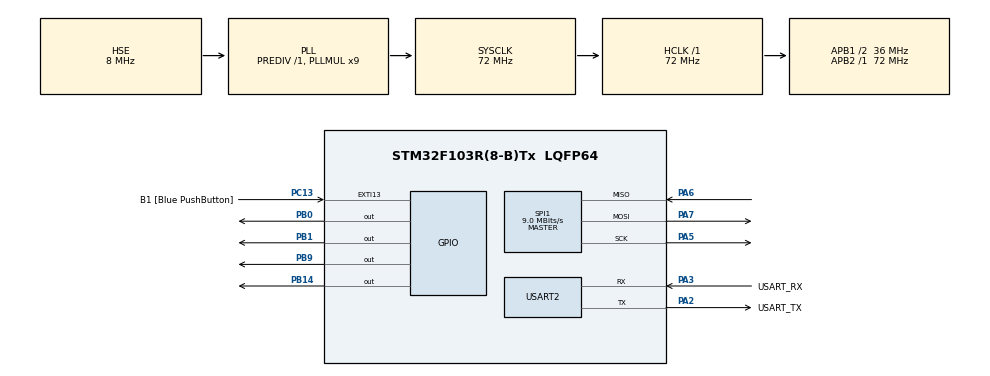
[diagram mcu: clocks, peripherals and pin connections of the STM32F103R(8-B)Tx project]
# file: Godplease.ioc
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Mcu.Family=STM32F1
Mcu.Name=STM32F103R(8-B)Tx
Mcu.Package=LQFP64
NVIC.EXTI15_10_IRQn=true\:0\:0\:false\:false\:true\:true\:true\:true
NVIC.PriorityGroup=NVIC_PRIORITYGROUP_4
PA13.GPIO_Label=TMS
PA13.Mode=Serial_Wire
PA13.Signal=SYS_JTMS-SWDIO
PA14.GPIO_Label=TCK
PA14.Mode=Serial_Wire
PA14.Signal=SYS_JTCK-SWCLK
PA2.GPIO_Label=USART_TX
PA2.GPIO_Mode=GPIO_MODE_AF_PP
PA2.GPIO_PuPd=GPIO_NOPULL
PA2.GPIO_Speed=GPIO_SPEED_FREQ_LOW
PA2.Mode=Asynchronous
PA2.Signal=USART2_TX
PA3.GPIO_Label=USART_RX
PA3.GPIO_Mode=GPIO_MODE_AF_PP
PA3.GPIO_PuPd=GPIO_NOPULL
PA3.GPIO_Speed=GPIO_SPEED_FREQ_LOW
PA3.Mode=Asynchronous
PA3.Signal=USART2_RX
PA5.Mode=Full_Duplex_Master
PA5.Signal=SPI1_SCK
PA6.Mode=Full_Duplex_Master
PA6.Signal=SPI1_MISO
PA7.Mode=Full_Duplex_Master
PA7.Signal=SPI1_MOSI
PB0.Signal=GPIO_Output
PB1.Signal=GPIO_Output
PB14.Signal=GPIO_Output
PB9.Signal=GPIO_Output
PC13-TAMPER-RTC.GPIO_Label=B1 [Blue PushButton]
PC13-TAMPER-RTC.GPIO_PuPd=GPIO_NOPULL
PC13-TAMPER-RTC.Signal=GPXTI13
PC14-OSC32_IN.Signal=RCC_OSC32_IN
PC15-OSC32_OUT.Signal=RCC_OSC32_OUT
PD0-OSC_IN.Mode=HSE-External-Oscillator
PD0-OSC_IN.Signal=RCC_OSC_IN
PD1-OSC_OUT.Mode=HSE-External-Oscillator
PD1-OSC_OUT.Signal=RCC_OSC_OUT
ProjectManager.HeapSize=0x200
ProjectManager.StackSize=0x400
ProjectManager.TargetToolchain=STM32CubeIDE
RCC.AHBFreq_Value=72000000
RCC.APB1CLKDivider=RCC_HCLK_DIV2
RCC.APB1Freq_Value=36000000
RCC.APB1TimFreq_Value=72000000
RCC.APB2Freq_Value=72000000
RCC.APB2TimFreq_Value=72000000
RCC.HCLKFreq_Value=72000000
RCC.PLLMUL=RCC_PLL_MUL9
RCC.PLLSourceVirtual=RCC_PLLSOURCE_HSE
RCC.RTCClockSelection=RCC_RTCCLKSOURCE_LSE
RCC.SYSCLKFreq_VALUE=72000000
RCC.SYSCLKSource=RCC_SYSCLKSOURCE_PLLCLK
RCC.USBFreq_Value=72000000
SPI1.BaudRatePrescaler=SPI_BAUDRATEPRESCALER_8
SPI1.CalculateBaudRate=9.0 MBits/s
SPI1.Direction=SPI_DIRECTION_2LINES
SPI1.Mode=SPI_MODE_MASTER
SPI1.VirtualType=VM_MASTER
TIM2.Prescaler=71
USART2.VirtualMode=VM_ASYNC
VP_TIM2_VS_ClockSourceINT.Mode=Internal
board=NUCLEO-F103RB

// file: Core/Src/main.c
/* USER CODE BEGIN Header */
/**
******************************************************************************
* @file : main.c
* @brief : Main program body
******************************************************************************
* @attention
*
* Copyright (c) 2025 STMicroelectronics.
* All rights reserved.
*
* This software is licensed under terms that can be found in the LICENSE file
* in the root directory of this software component.
* If no LICENSE file comes with this software, it is provided AS-IS.
*
******************************************************************************
*/
/* USER CODE END Header */
#include "main.h"
#include "stdio.h"
#include "RC522.h"
#include "string.h"

SPI_HandleTypeDef hspi1;

TIM_HandleTypeDef htim2;

UART_HandleTypeDef huart2;

/* USER CODE BEGIN PV */
uint8_t status;
uint8_t str[16];
uint8_t sNum[5];
uint8_t lastCardDetected = 0; // 0 = no card, 1 = student1, 2 = student2

char *msg1 = "STUDENT 1 proxy received\r\n";
char *msg2 = "STUDENT 2 proxy received\r\n";

/* USER CODE END PV */

void SystemClock_Config(void);
static void MX_GPIO_Init(void);
static void MX_USART2_UART_Init(void);
static void MX_SPI1_Init(void);
static void MX_TIM2_Init(void);

int main(void)
{

  /* MCU Configuration--------------------------------------------------------*/

  /* Reset of all peripherals, Initializes the Flash interface and the Systick. */
  HAL_Init();

  /* Configure the system clock */
  SystemClock_Config();

  /* Initialize all configured peripherals */
  MX_GPIO_Init();
  MX_USART2_UART_Init();
  MX_SPI1_Init();
  MX_TIM2_Init();
  HAL_TIM_Base_Start(&htim2);

  MFRC522_Init();
  /* USER CODE BEGIN 2 */

HAL_UART_Transmit(&huart2, (uint8_t*)"RFID Reader Started\r\n", 21, HAL_MAX_DELAY);

  /* USER CODE END 2 */

  /* Infinite loop */
while (1)
{
	status = MFRC522_Request(PICC_REQIDL, str);
		    status = MFRC522_Anticoll(str);

		    memcpy(sNum, str, 5);
		    HAL_Delay(200);

		    uint8_t currentCard = 0;
		    uint8_t validCardDetected = 0;

		    if(sNum[0] == 227 && sNum[1] == 32 && sNum[2] == 69 && sNum[3] == 53 && sNum[4] == 24)
		    {
		        currentCard = 1;

		        if(lastCardDetected != 1)
		        {

		        	validCardDetected = 1;
		            HAL_UART_Transmit(&huart2, (uint8_t*)msg1, strlen(msg1), HAL_MAX_DELAY);

		            HAL_GPIO_WritePin(GPIOB, GPIO_PIN_1, GPIO_PIN_SET);
		        }
		    }
		    else if(sNum[0] == 35 && sNum[1] == 32 && sNum[2] == 83 && sNum[3] == 245 && sNum[4] == 174)
		    {
		        currentCard = 2;

		        if(lastCardDetected != 2)
		        {

		        	validCardDetected = 1;
		            HAL_UART_Transmit(&huart2, (uint8_t*)msg2, strlen(msg2), HAL_MAX_DELAY);

		            HAL_GPIO_WritePin(GPIOB, GPIO_PIN_1, GPIO_PIN_SET);
		        }
		    }

		    // Control buzzer - HIGH when valid card is detected
		    if(validCardDetected)
		    {
		        HAL_GPIO_WritePin(GPIOB, GPIO_PIN_1, GPIO_PIN_SET);
		        HAL_Delay(2000);
		    }

		    lastCardDetected = currentCard;

		    // Ensure buzzer is LOW at the end of each loop iteration
		    HAL_GPIO_WritePin(GPIOB, GPIO_PIN_1, GPIO_PIN_RESET);

}
}

void SystemClock_Config(void)
{
  RCC_OscInitTypeDef RCC_OscInitStruct = {0};
  RCC_ClkInitTypeDef RCC_ClkInitStruct = {0};

  /** Initializes the RCC Oscillators according to the specified parameters
  * in the RCC_OscInitTypeDef structure.
  */
  RCC_OscInitStruct.OscillatorType = RCC_OSCILLATORTYPE_HSE;
  RCC_OscInitStruct.HSEState = RCC_HSE_ON;
  RCC_OscInitStruct.HSEPredivValue = RCC_HSE_PREDIV_DIV1;
  RCC_OscInitStruct.HSIState = RCC_HSI_ON;
  RCC_OscInitStruct.PLL.PLLState = RCC_PLL_ON;
  RCC_OscInitStruct.PLL.PLLSource = RCC_PLLSOURCE_HSE;
  RCC_OscInitStruct.PLL.PLLMUL = RCC_PLL_MUL9;
  if (HAL_RCC_OscConfig(&RCC_OscInitStruct) != HAL_OK)
  {
    Error_Handler();
  }

  /** Initializes the CPU, AHB and APB buses clocks
  */
  RCC_ClkInitStruct.ClockType = RCC_CLOCKTYPE_HCLK|RCC_CLOCKTYPE_SYSCLK
                              |RCC_CLOCKTYPE_PCLK1|RCC_CLOCKTYPE_PCLK2;
  RCC_ClkInitStruct.SYSCLKSource = RCC_SYSCLKSOURCE_PLLCLK;
  RCC_ClkInitStruct.AHBCLKDivider = RCC_SYSCLK_DIV1;
  RCC_ClkInitStruct.APB1CLKDivider = RCC_HCLK_DIV2;
  RCC_ClkInitStruct.APB2CLKDivider = RCC_HCLK_DIV1;

  if (HAL_RCC_ClockConfig(&RCC_ClkInitStruct, FLASH_LATENCY_2) != HAL_OK)
  {
    Error_Handler();
  }
}

static void MX_SPI1_Init(void)
{

  /* SPI1 parameter configuration*/
  hspi1.Instance = SPI1;
  hspi1.Init.Mode = SPI_MODE_MASTER;
  hspi1.Init.Direction = SPI_DIRECTION_2LINES;
  hspi1.Init.DataSize = SPI_DATASIZE_8BIT;
  hspi1.Init.CLKPolarity = SPI_POLARITY_LOW;
  hspi1.Init.CLKPhase = SPI_PHASE_1EDGE;
  hspi1.Init.NSS = SPI_NSS_SOFT;
  hspi1.Init.BaudRatePrescaler = SPI_BAUDRATEPRESCALER_8;
  hspi1.Init.FirstBit = SPI_FIRSTBIT_MSB;
  hspi1.Init.TIMode = SPI_TIMODE_DISABLE;
  hspi1.Init.CRCCalculation = SPI_CRCCALCULATION_DISABLE;
  hspi1.Init.CRCPolynomial = 10;
  if (HAL_SPI_Init(&hspi1) != HAL_OK)
  {
    Error_Handler();
  }

}

static void MX_TIM2_Init(void)
{

  TIM_ClockConfigTypeDef sClockSourceConfig = {0};
  TIM_MasterConfigTypeDef sMasterConfig = {0};

  htim2.Instance = TIM2;
  htim2.Init.Prescaler = 71;
  htim2.Init.CounterMode = TIM_COUNTERMODE_UP;
  htim2.Init.Period = 65535;
  htim2.Init.ClockDivision = TIM_CLOCKDIVISION_DIV1;
  htim2.Init.AutoReloadPreload = TIM_AUTORELOAD_PRELOAD_DISABLE;
  if (HAL_TIM_Base_Init(&htim2) != HAL_OK)
  {
    Error_Handler();
  }
  sClockSourceConfig.ClockSource = TIM_CLOCKSOURCE_INTERNAL;
  if (HAL_TIM_ConfigClockSource(&htim2, &sClockSourceConfig) != HAL_OK)
  {
    Error_Handler();
  }
  sMasterConfig.MasterOutputTrigger = TIM_TRGO_RESET;
  sMasterConfig.MasterSlaveMode = TIM_MASTERSLAVEMODE_DISABLE;
  if (HAL_TIMEx_MasterConfigSynchronization(&htim2, &sMasterConfig) != HAL_OK)
  {
    Error_Handler();
  }

}

static void MX_USART2_UART_Init(void)
{

  huart2.Instance = USART2;
  huart2.Init.BaudRate = 115200;
  huart2.Init.WordLength = UART_WORDLENGTH_8B;
  huart2.Init.StopBits = UART_STOPBITS_1;
  huart2.Init.Parity = UART_PARITY_NONE;
  huart2.Init.Mode = UART_MODE_TX_RX;
  huart2.Init.HwFlowCtl = UART_HWCONTROL_NONE;
  huart2.Init.OverSampling = UART_OVERSAMPLING_16;
  if (HAL_UART_Init(&huart2) != HAL_OK)
  {
    Error_Handler();
  }

}

static void MX_GPIO_Init(void)
{
  GPIO_InitTypeDef GPIO_InitStruct = {0};

  /* GPIO Ports Clock Enable */
  __HAL_RCC_GPIOC_CLK_ENABLE();
  __HAL_RCC_GPIOD_CLK_ENABLE();
  __HAL_RCC_GPIOA_CLK_ENABLE();
  __HAL_RCC_GPIOB_CLK_ENABLE();

  /*Configure GPIO pin Output Level */
  HAL_GPIO_WritePin(GPIOB, GPIO_PIN_0|GPIO_PIN_1|GPIO_PIN_14|GPIO_PIN_9, GPIO_PIN_RESET);

  /*Configure GPIO pin : B1_Pin */
  GPIO_InitStruct.Pin = B1_Pin;
  GPIO_InitStruct.Mode = GPIO_MODE_IT_RISING;
  GPIO_InitStruct.Pull = GPIO_NOPULL;
  HAL_GPIO_Init(B1_GPIO_Port, &GPIO_InitStruct);

  /*Configure GPIO pins : PB0 PB1 PB14 PB9 */
  GPIO_InitStruct.Pin = GPIO_PIN_0|GPIO_PIN_1|GPIO_PIN_14|GPIO_PIN_9;
  GPIO_InitStruct.Mode = GPIO_MODE_OUTPUT_PP;
  GPIO_InitStruct.Pull = GPIO_NOPULL;
  GPIO_InitStruct.Speed = GPIO_SPEED_FREQ_LOW;
  HAL_GPIO_Init(GPIOB, &GPIO_InitStruct);

  /* EXTI interrupt init*/
  HAL_NVIC_SetPriority(EXTI15_10_IRQn, 0, 0);
  HAL_NVIC_EnableIRQ(EXTI15_10_IRQn);

}

void Error_Handler(void)
{
__disable_irq();
while (1)
{
}
}
